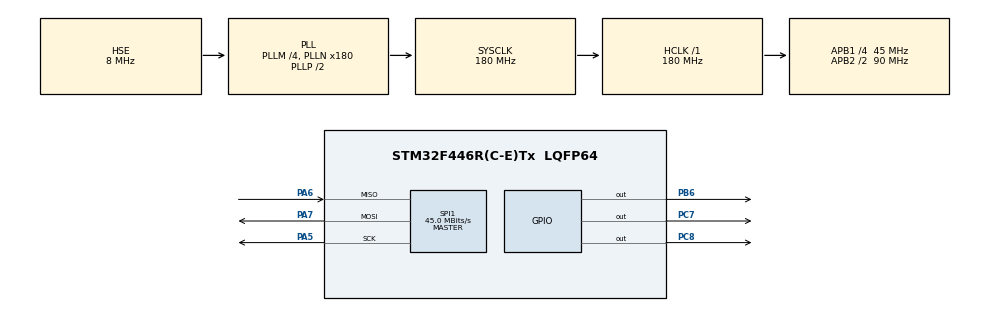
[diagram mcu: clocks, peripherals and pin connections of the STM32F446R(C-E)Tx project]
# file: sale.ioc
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Mcu.Family=STM32F4
Mcu.Name=STM32F446R(C-E)Tx
Mcu.Package=LQFP64
NVIC.PriorityGroup=NVIC_PRIORITYGROUP_4
PA5.Mode=Full_Duplex_Master
PA5.Signal=SPI1_SCK
PA6.Mode=Full_Duplex_Master
PA6.Signal=SPI1_MISO
PA7.Mode=Full_Duplex_Master
PA7.Signal=SPI1_MOSI
PB6.Signal=GPIO_Output
PC7.Signal=GPIO_Output
PC8.Signal=GPIO_Output
PH0-OSC_IN.Mode=HSE-External-Clock-Source
PH0-OSC_IN.Signal=RCC_OSC_IN
PH1-OSC_OUT.Mode=HSE-External-Clock-Source
PH1-OSC_OUT.Signal=RCC_OSC_OUT
ProjectManager.HeapSize=0x200
ProjectManager.StackSize=0x400
ProjectManager.TargetToolchain=STM32CubeIDE
RCC.AHBFreq_Value=180000000
RCC.APB1CLKDivider=RCC_HCLK_DIV4
RCC.APB1Freq_Value=45000000
RCC.APB1TimFreq_Value=90000000
RCC.APB2CLKDivider=RCC_HCLK_DIV2
RCC.APB2Freq_Value=90000000
RCC.APB2TimFreq_Value=180000000
RCC.CortexFreq_Value=180000000
RCC.HCLKFreq_Value=180000000
RCC.HSE_VALUE=8000000
RCC.PLLM=4
RCC.PLLN=180
RCC.PLLSourceVirtual=RCC_PLLSOURCE_HSE
RCC.SYSCLKFreq_VALUE=180000000
RCC.SYSCLKSource=RCC_SYSCLKSOURCE_PLLCLK
RCC.USBFreq_Value=180000000
RCC.VCOOutputFreq_Value=360000000
SPI1.CalculateBaudRate=45.0 MBits/s
SPI1.Direction=SPI_DIRECTION_2LINES
SPI1.Mode=SPI_MODE_MASTER
SPI1.VirtualType=VM_MASTER
board=custom

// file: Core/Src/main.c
/* USER CODE BEGIN Header */
/**
  ******************************************************************************
  * @file           : main.c
  * @brief          : Main program body
  ******************************************************************************
  * @attention
  *
  * <h2><center>&copy; Copyright (c) 2021 STMicroelectronics.
  * All rights reserved.</center></h2>
  *
  * This software component is licensed by ST under BSD 3-Clause license,
  * the "License"; You may not use this file except in compliance with the
  * License. You may obtain a copy of the License at:
  *                        opensource.org/licenses/BSD-3-Clause
  *
  ******************************************************************************
  */
/* USER CODE END Header */
#include "main.h"
#include "spi.h"
#include "gpio.h"

/* USER CODE BEGIN Includes */
#include "NRF24L01.h"
#include "string.h"
/* USER CODE END Includes */

void SystemClock_Config(void);

/* USER CODE BEGIN 0 */

//uint8_t RxAddress[] = {0x00,0xDD,0xCC,0xBB,0xAA};
//uint8_t RxData[32];

uint8_t data[50];

uint8_t TxAddress[] = {0xEE,0xDD,0xCC,0xBB,0xAA};
uint8_t TxData = 12;

/* USER CODE END 0 */

int main(void)
{

  /* MCU Configuration--------------------------------------------------------*/

  /* Reset of all peripherals, Initializes the Flash interface and the Systick. */
  HAL_Init();

  /* Configure the system clock */
  SystemClock_Config();

  /* Initialize all configured peripherals */
  MX_GPIO_Init();
  MX_SPI1_Init();
  /* USER CODE BEGIN 2 */

  NRF24_Init();

//  NRF24_RxMode(RxAddress, 10);

  NRF24_TxMode(TxAddress, 10);

  NRF24_ReadAll(data);
  /* USER CODE END 2 */

  /* Infinite loop */
  while (1)
  {

    /* USER CODE BEGIN 3 */

/*	  if (isDataAvailable(2) == 1)
	  {
		  NRF24_Receive(RxData);
		  HAL_UART_Transmit(&huart2, RxData, strlen((char *)RxData), 1000);
	  }
	*/

	  if (NRF24_Transmit(TxData) == 1)
	  {
		  HAL_GPIO_TogglePin(GPIOC, GPIO_PIN_8);
	  }

	  HAL_Delay(1000);

  }
  /* USER CODE END 3 */
}

void SystemClock_Config(void)
{
  RCC_OscInitTypeDef RCC_OscInitStruct = {0};
  RCC_ClkInitTypeDef RCC_ClkInitStruct = {0};

  /** Configure the main internal regulator output voltage
  */
  __HAL_RCC_PWR_CLK_ENABLE();
  __HAL_PWR_VOLTAGESCALING_CONFIG(PWR_REGULATOR_VOLTAGE_SCALE1);

  /** Initializes the RCC Oscillators according to the specified parameters
  * in the RCC_OscInitTypeDef structure.
  */
  RCC_OscInitStruct.OscillatorType = RCC_OSCILLATORTYPE_HSE;
  RCC_OscInitStruct.HSEState = RCC_HSE_BYPASS;
  RCC_OscInitStruct.PLL.PLLState = RCC_PLL_ON;
  RCC_OscInitStruct.PLL.PLLSource = RCC_PLLSOURCE_HSE;
  RCC_OscInitStruct.PLL.PLLM = 4;
  RCC_OscInitStruct.PLL.PLLN = 180;
  RCC_OscInitStruct.PLL.PLLP = RCC_PLLP_DIV2;
  RCC_OscInitStruct.PLL.PLLQ = 2;
  RCC_OscInitStruct.PLL.PLLR = 2;
  if (HAL_RCC_OscConfig(&RCC_OscInitStruct) != HAL_OK)
  {
    Error_Handler();
  }

  /** Activate the Over-Drive mode
  */
  if (HAL_PWREx_EnableOverDrive() != HAL_OK)
  {
    Error_Handler();
  }

  /** Initializes the CPU, AHB and APB buses clocks
  */
  RCC_ClkInitStruct.ClockType = RCC_CLOCKTYPE_HCLK|RCC_CLOCKTYPE_SYSCLK
                              |RCC_CLOCKTYPE_PCLK1|RCC_CLOCKTYPE_PCLK2;
  RCC_ClkInitStruct.SYSCLKSource = RCC_SYSCLKSOURCE_PLLCLK;
  RCC_ClkInitStruct.AHBCLKDivider = RCC_SYSCLK_DIV1;
  RCC_ClkInitStruct.APB1CLKDivider = RCC_HCLK_DIV4;
  RCC_ClkInitStruct.APB2CLKDivider = RCC_HCLK_DIV2;

  if (HAL_RCC_ClockConfig(&RCC_ClkInitStruct, FLASH_LATENCY_5) != HAL_OK)
  {
    Error_Handler();
  }
}

void Error_Handler(void)
{
  __disable_irq();
  while (1)
  {
  }
}
